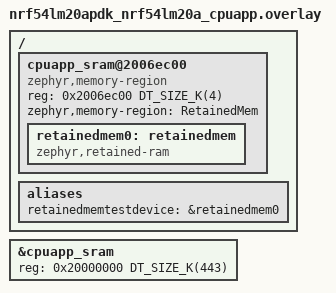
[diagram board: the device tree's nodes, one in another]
/ {
	cpuapp_sram@2006ec00 {
		compatible = "zephyr,memory-region", "mmio-sram";
		reg = <0x2006ec00 DT_SIZE_K(4)>;
		zephyr,memory-region = "RetainedMem";
		status = "okay";

		retainedmem0: retainedmem {
			compatible = "zephyr,retained-ram";
			status = "okay";
		};
	};

	aliases {
		retainedmemtestdevice = &retainedmem0;
	};
};

&cpuapp_sram {
	/* Shrink SRAM size to avoid overlap with retained memory region:
	 * Available - FLPR - retainedmem0
	 * 511 - 64 - 4 = 443KB = 0x6ec00
	 */
	reg = <0x20000000 DT_SIZE_K(443)>;
	ranges = <0x0 0x20000000 0x6ec00>;
};
